AUTOSAR XML (schema 00050)
package /ComponentTypes
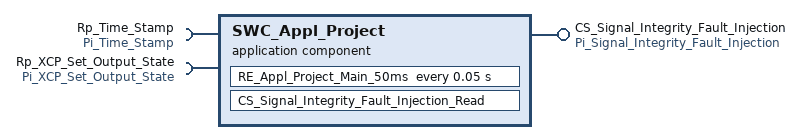
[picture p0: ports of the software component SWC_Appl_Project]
  application sw component type SWC_Appl_Project
    require port Rp_Time_Stamp: nonqueued-receiver-com-spec{data-element=De_StbM_TimeStampType, filter=data-filter-type=ALWAYS, init-value=fields=[timeBaseStatus:0, nanoseconds:0, seconds:0, secondsHi:0]}, required-interface=Pi_Time_Stamp
    provide port CS_Signal_Integrity_Fault_Injection: server-com-spec{operation=Read, queue-length=1}, provided-interface=Pi_Signal_Integrity_Fault_Injection
    require port Rp_XCP_Set_Output_State: nonqueued-receiver-com-spec{data-element=De_XCP_Set_Output, filter=data-filter-type=ALWAYS, init-value=constant-reference=C_XCP_Output_State}, required-interface=Pi_XCP_Set_Output_State
    behavior SWC_Appl_Project_InternalBehavior: handle-termination-and-restart=NO-SUPPORT
      timing event TMT_RE_Appl_Project_Main_50ms: start-on-event=RE_Appl_Project_Main_50ms, period=0.05
      operation invoked event OIT_CS_Signal_Integrity_Fault_Injection_Read_CS_Signal_Integrity_Fault_Injection_Read: start-on-event=CS_Signal_Integrity_Fault_Injection_Read, operation=CS_Signal_Integrity_Fault_Injection.Read
      runnable RE_Appl_Project_Main_50ms
        data-receive-point-by-arguments:
          access REC_Rp_Time_Stamp_De_StbM_TimeStampType: accessed-variable=Rp_Time_Stamp.De_StbM_TimeStampType
          access REC_Rp_XCP_Set_Output_State_De_XCP_Set_Output: accessed-variable=Rp_XCP_Set_Output_State.De_XCP_Set_Output
      runnable CS_Signal_Integrity_Fault_Injection_Read
  swc implementation SWC_Appl_Project_Implementation: behavior=SWC_Appl_Project_InternalBehavior
